# SIM3L168_A register map
File version: 1
CPU: 
Registers are 32-bit, read-write, reset 0x0 unless marked. A register's access mark holds for its fields unless they carry their own. Offsets are from the block's base; [hi:lo] are bit positions; {n}, {i} and the like mark numbered series.

## AES_0
Base 0x40027000
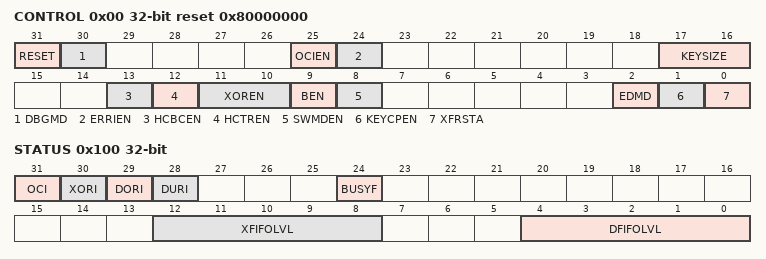
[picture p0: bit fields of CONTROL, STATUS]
0x00 CONTROL reset 0x80000000 — Module Control
  [31] RESET — Module Soft Reset.
    0=INACTIVE (AES module is not in soft reset.); 1=ACTIVE (AES module is in soft reset and none of the module bits can be accessed.)
  [30] DBGMD — AES Debug Mode.
    0=HALT (A debug breakpoint will cause the AES module to halt.); 1=RUN (The AES module will continue to operate while the core is halted in debug mode.)
  [25] OCIEN — Operation Complete Interrupt Enable.
    0=DISABLED (Disable the operation complete interrupt.); 1=ENABLED (Enable the operation complete interrupt. An interrupt is generated when the Operation Complete Interrupt (OCI) flag is set.)
  [24] ERRIEN — Error Interrupt Enable.
    0=DISABLED (Disable the error interrupt.); 1=ENABLED (Enable the error interrupt. An interrupt is generated when the Input/Output Data FIFO Overun (DORI), Input/Output Data FIFO Underun (DURI), or XOR Data FIFO Overrun (XORI) flags are set.)
  [17:16] KEYSIZE — Keystore Size Select.
    0=KEY128 (Key is composed of 128 bits.); 1=KEY192 (Key is composed of 192 bits.); 2=KEY256 (Key is composed of 256 bits.)
  [13] HCBCEN — Hardware Cipher-Block Chaining Mode Enable.
    0=DISABLED (Disable hardware cipher-block chaining (CBC) mode.); 1=ENABLED (Enable hardware cipher-block chaining (CBC) mode.)
  [12] HCTREN — Hardware Counter Mode Enable.
    0=DISABLED (Disable hardware counter mode.); 1=ENABLED (Enable hardware counter mode.)
  [11:10] XOREN — XOR Enable.
    0=XOR_DISABLED (Disable the XOR paths.); 1=XOR_INPUT (Enable the XOR input path, disable the XOR output path.); 2=XOR_OUTPUT (Disable the XOR input path, enable the XOR output path.)
  [9] BEN — Bypass AES Operation Enable.
    0=DISABLED (Do not bypass AES operations.); 1=ENABLED (Bypass AES operations.)
  [8] SWMDEN — Software Mode Enable.
    0=DISABLED (Disable software mode.); 1=ENABLED (Enable software mode.)
  [2] EDMD — Encryption/Decryption Mode.
    0=DECRYPT (AES module performs a decryption operation); 1=ENCRYPT (AES module performs an encryption operation.)
  [1] KEYCPEN — Key Capture Enable.
    0=DISABLED (Disable key capture.); 1=ENABLED (Enable key capture.)
  [0] XFRSTA — AES Transfer Start.
    1=START (Start the AES operation.)
0x10 XFRSIZE — Number of Blocks
  [10:0] XFRSIZE — Transfer Size.
0x20 DATAFIFO read-has-side-effects — Input/Output Data FIFO Access
  [31:0] DATAFIFO — Input/Output Data FIFO Access.
0x30 XORFIFO — XOR Data FIFO Access
  [31:0] XORFIFO — XOR Data FIFO Access.
{0x40+0x10*i} HWKEY{i} (i=0..7) — Hardware Key Word {i}
  [31:0] HWKEY{i} — Hardware Key Word {i}.
{0xC0+0x10*i} HWCTR{i} (i=0..3) — Hardware Counter Word {i}
  [31:0] HWCTR{i} — Hardware Counter Word {i}.
0x100 STATUS — Module Status
  [31] OCI — Operation Complete Interrupt Flag.
    0=NOT_SET (AES operation complete interrupt has not occurred.); 1=SET (AES operation complete interrupt occurred.)
  [30] XORI — XOR Data FIFO Overrun Interrupt Flag.
    0=NOT_SET (No XOR data FIFO overrun.); 1=SET (An XOR data FIFO overrun has occurred.)
  [29] DORI — Input/Output Data FIFO Overrun Interrupt Flag.
    0=NOT_SET (No input/output data FIFO overrun.); 1=SET (An input/output data FIFO overrun has occurred.)
  [28] DURI — Input/Output Data FIFO Underrun Interrupt Flag.
    0=NOT_SET (No input/output data FIFO underrun.); 1=SET (An input/output data FIFO underrun has occurred.)
  [24] BUSYF ro — Module Busy Flag.
    0=NOT_SET (AES module is not busy.); 1=SET (AES module is completing an operation.)
  [12:8] XFIFOLVL ro — XOR Data FIFO Level.
    0=EMPTY (XOR data FIFO is empty.); 1=1_BYTE (XOR data FIFO contains 1 byte.); {v}={v}_BYTES (XOR data FIFO contains {v} bytes.) (v=2..15); 16=FULL (XOR data FIFO contains 16 bytes (full).)
  [4:0] DFIFOLVL ro — Input/Output Data FIFO Level.
    0=EMPTY (Input/Output data FIFO is empty.); 1=1_BYTE (Input/Output data FIFO contains 1 byte.); {v}={v}_BYTES (Input/Output data FIFO contains {v} bytes.) (v=2..15); 16=FULL (Input/Output data FIFO contains 16 bytes (full).)
